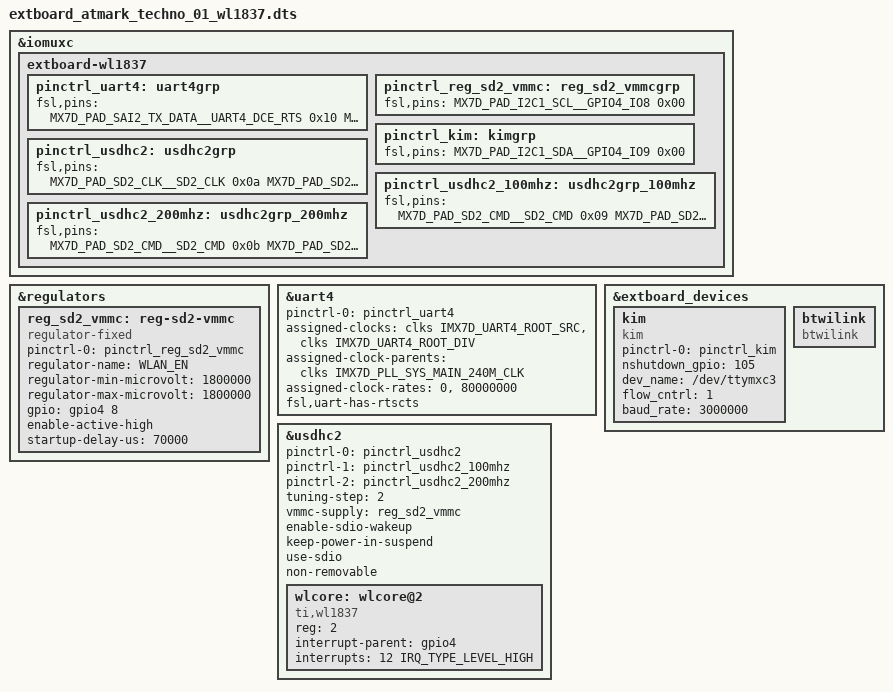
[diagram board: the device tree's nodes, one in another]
/*
 * DTS overlay for converting ti,tilcdc,slave binding to new binding.
 *
 * Copyright (C) 2016 Atmark Techno, Inc. All Rights Reserved.
 * Author: Daisuke Mizobuchi <mizo@atmark-techno.com>
 *
 * This program is free software; you can redistribute it and/or
 * modify it under the terms of the GNU General Public License
 * version 2 as published by the Free Software Foundation.
 */

#include <dt-bindings/clock/imx7d-clock.h>
#include <dt-bindings/gpio/gpio.h>
#include <dt-bindings/interrupt-controller/arm-gic.h>
#include "../../../../arch/arm/boot/dts/imx7d-pinfunc.h"

/dts-v1/;
/plugin/;
/ {
	fragment@0 {
		target = <&iomuxc>;
		__overlay__ {
			extboard-wl1837 {
				pinctrl_uart4: uart4grp {
					fsl,pins = <
						MX7D_PAD_SAI2_TX_DATA__UART4_DCE_RTS	0x10	/* CON7_36 */
						MX7D_PAD_SAI2_RX_DATA__UART4_DCE_CTS	0x00	/* CON7_37 */
						MX7D_PAD_SAI2_TX_BCLK__UART4_DCE_TX	0x00	/* CON7_38 */
						MX7D_PAD_SAI2_TX_SYNC__UART4_DCE_RX 	0x70	/* CON7_39 */
					>;
				};

				pinctrl_reg_sd2_vmmc: reg_sd2_vmmcgrp {
					fsl,pins = <
						MX7D_PAD_I2C1_SCL__GPIO4_IO8		0x00	/* CON7_11(WLAN_EN) */
					>;
				};

				pinctrl_kim: kimgrp {
					fsl,pins = <
						MX7D_PAD_I2C1_SDA__GPIO4_IO9		0x00	/* CON7_12(WL1837_BT_EN) */
					>;
				};

				pinctrl_usdhc2: usdhc2grp {
					fsl,pins = <
						MX7D_PAD_SD2_CLK__SD2_CLK	0x0a	/* CON7_18 */
						MX7D_PAD_SD2_CMD__SD2_CMD	0x0a	/* CON7_19 */
						MX7D_PAD_SD2_DATA0__SD2_DATA0	0x08	/* CON7_20 */
						MX7D_PAD_SD2_DATA1__SD2_DATA1	0x08	/* CON7_21 */
						MX7D_PAD_SD2_DATA2__SD2_DATA2	0x08	/* CON7_22 */
						MX7D_PAD_SD2_DATA3__SD2_DATA3	0x08	/* CON7_23 */
					>;
				};

				pinctrl_usdhc2_100mhz: usdhc2grp_100mhz {
					fsl,pins = <
						MX7D_PAD_SD2_CMD__SD2_CMD	0x09
						MX7D_PAD_SD2_CLK__SD2_CLK	0x09
						MX7D_PAD_SD2_DATA0__SD2_DATA0	0x08
						MX7D_PAD_SD2_DATA1__SD2_DATA1	0x08
						MX7D_PAD_SD2_DATA2__SD2_DATA2	0x08
						MX7D_PAD_SD2_DATA3__SD2_DATA3	0x08
					>;
				};

				pinctrl_usdhc2_200mhz: usdhc2grp_200mhz {
					fsl,pins = <
						MX7D_PAD_SD2_CMD__SD2_CMD	0x0b
						MX7D_PAD_SD2_CLK__SD2_CLK	0x09
						MX7D_PAD_SD2_DATA0__SD2_DATA0	0x08
						MX7D_PAD_SD2_DATA1__SD2_DATA1	0x08
						MX7D_PAD_SD2_DATA2__SD2_DATA2	0x08
						MX7D_PAD_SD2_DATA3__SD2_DATA3	0x08
					>;
				};
			};
		};
	};

	fragment@1 {
		target = <&regulators>;
		__overlay__ {
			reg_sd2_vmmc: reg-sd2-vmmc {
				compatible = "regulator-fixed";
				pinctrl-names = "default";
				pinctrl-0 = <&pinctrl_reg_sd2_vmmc>;
				regulator-name = "WLAN_EN";
				regulator-min-microvolt = <1800000>;
				regulator-max-microvolt = <1800000>;
				gpio = <&gpio4 8 GPIO_ACTIVE_HIGH>;
				enable-active-high;
				startup-delay-us = <70000>;
			};
		};
	};

	fragment@2 {
		target = <&uart4>;
		__overlay__ {
			pinctrl-names = "default";
			pinctrl-0 = <&pinctrl_uart4>;
			assigned-clocks = <&clks IMX7D_UART4_ROOT_SRC>, <&clks IMX7D_UART4_ROOT_DIV>;
			assigned-clock-parents = <&clks IMX7D_PLL_SYS_MAIN_240M_CLK>;
			assigned-clock-rates = <0>, <80000000>;
			fsl,uart-has-rtscts;
			status = "okay";
		};
	};

	fragment@3 {
		target = <&extboard_devices>;
		__overlay__ {
			kim {
				compatible = "kim";
				pinctrl-names = "default";
				pinctrl-0 = <&pinctrl_kim>;
				nshutdown_gpio = <105>;	/* BT_EN: GPIO4_IO9 */
				dev_name = "/dev/ttymxc3";
				flow_cntrl = <1>;
				baud_rate = <3000000>;
			};
		};
	};

	fragment@4 {
		target = <&extboard_devices>;
		__overlay__ {
			btwilink {
				compatible = "btwilink";
			};
		};
	};

	fragment@5 {
		target = <&usdhc2>;
		__overlay__ {
			pinctrl-names = "default", "state_100mhz", "state_200mhz";
			pinctrl-0 = <&pinctrl_usdhc2>;
			pinctrl-1 = <&pinctrl_usdhc2_100mhz>;
			pinctrl-2 = <&pinctrl_usdhc2_200mhz>;
			tuning-step = <2>;
			vmmc-supply = <&reg_sd2_vmmc>;
			enable-sdio-wakeup;
			keep-power-in-suspend;
			use-sdio;
			non-removable;
			status = "okay";

			#address-cells = <1>;
			#size-cells = <0>;
			wlcore: wlcore@2 {
				compatible = "ti,wl1837";
				reg = <2>;
				interrupt-parent = <&gpio4>;
				interrupts = <12 IRQ_TYPE_LEVEL_HIGH>;
			};
		};
	};
};
